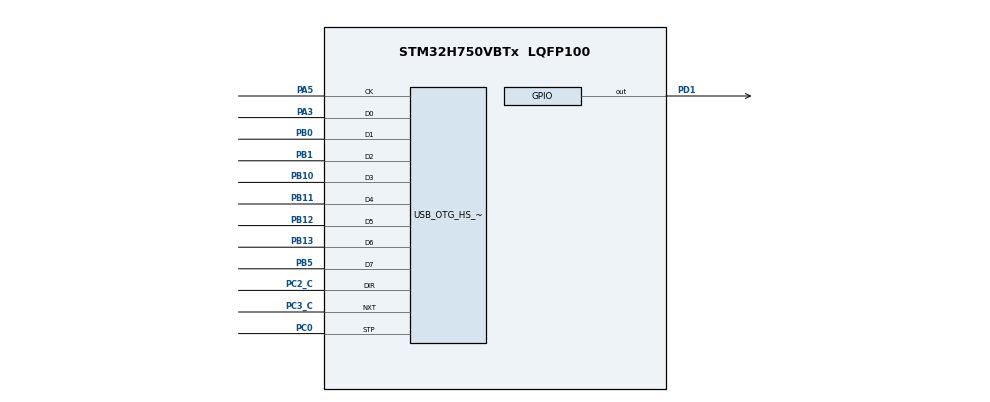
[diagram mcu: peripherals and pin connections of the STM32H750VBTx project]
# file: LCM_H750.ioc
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CORTEX_M7.AccessPermission-Cortex_Memory_Protection_Unit_Region0_Settings=MPU_REGION_FULL_ACCESS
CORTEX_M7.AccessPermission-Cortex_Memory_Protection_Unit_Region1_Settings=MPU_REGION_FULL_ACCESS
CORTEX_M7.AccessPermission-Cortex_Memory_Protection_Unit_Region2_Settings=MPU_REGION_FULL_ACCESS
CORTEX_M7.AccessPermission-Cortex_Memory_Protection_Unit_Region3_Settings=MPU_REGION_FULL_ACCESS
CORTEX_M7.AccessPermission_S-Cortex_Memory_Protection_Unit_Region1_Settings_S=MPU_REGION_FULL_ACCESS
CORTEX_M7.AccessPermission_S-Cortex_Memory_Protection_Unit_Region2_Settings_S=MPU_REGION_FULL_ACCESS
CORTEX_M7.AccessPermission_S-Cortex_Memory_Protection_Unit_Region3_Settings_S=MPU_REGION_FULL_ACCESS
CORTEX_M7.AccessPermission_Spec=MPU_REGION_FULL_ACCESS
CORTEX_M7.BaseAddress-Cortex_Memory_Protection_Unit_Region0_Settings=0x24000000
CORTEX_M7.BaseAddress-Cortex_Memory_Protection_Unit_Region1_Settings=0x30000000
CORTEX_M7.BaseAddress-Cortex_Memory_Protection_Unit_Region2_Settings=0x30040000
CORTEX_M7.BaseAddress-Cortex_Memory_Protection_Unit_Region3_Settings=0x38000000
CORTEX_M7.BaseAddress_S-Cortex_Memory_Protection_Unit_Region1_Settings_S=0x30000000
CORTEX_M7.BaseAddress_S-Cortex_Memory_Protection_Unit_Region2_Settings_S=0x30040000
CORTEX_M7.BaseAddress_S-Cortex_Memory_Protection_Unit_Region3_Settings_S=0x38000000
CORTEX_M7.BaseAddress_Spec=0x24000000
CORTEX_M7.CPU_DCache=Enabled
CORTEX_M7.CPU_ICache=Enabled
CORTEX_M7.DisableExec_Spec=MPU_INSTRUCTION_ACCESS_ENABLE
CORTEX_M7.Enable-Cortex_Memory_Protection_Unit_Region0_Settings=MPU_REGION_ENABLE
CORTEX_M7.Enable-Cortex_Memory_Protection_Unit_Region1_Settings=MPU_REGION_ENABLE
CORTEX_M7.Enable-Cortex_Memory_Protection_Unit_Region2_Settings=MPU_REGION_ENABLE
CORTEX_M7.Enable-Cortex_Memory_Protection_Unit_Region3_Settings=MPU_REGION_ENABLE
CORTEX_M7.Enable_S-Cortex_Memory_Protection_Unit_Region1_Settings_S=MPU_REGION_ENABLE
CORTEX_M7.Enable_S-Cortex_Memory_Protection_Unit_Region2_Settings_S=MPU_REGION_ENABLE
CORTEX_M7.Enable_S-Cortex_Memory_Protection_Unit_Region3_Settings_S=MPU_REGION_ENABLE
CORTEX_M7.IsBufferable-Cortex_Memory_Protection_Unit_Region0_Settings=MPU_ACCESS_BUFFERABLE
CORTEX_M7.IsBufferable-Cortex_Memory_Protection_Unit_Region1_Settings=MPU_ACCESS_BUFFERABLE
CORTEX_M7.IsBufferable-Cortex_Memory_Protection_Unit_Region2_Settings=MPU_ACCESS_BUFFERABLE
CORTEX_M7.IsBufferable-Cortex_Memory_Protection_Unit_Region3_Settings=MPU_ACCESS_BUFFERABLE
CORTEX_M7.IsBufferable_S-Cortex_Memory_Protection_Unit_Region1_Settings_S=MPU_ACCESS_BUFFERABLE
CORTEX_M7.IsBufferable_S-Cortex_Memory_Protection_Unit_Region2_Settings_S=MPU_ACCESS_BUFFERABLE
CORTEX_M7.IsBufferable_S-Cortex_Memory_Protection_Unit_Region3_Settings_S=MPU_ACCESS_BUFFERABLE
CORTEX_M7.IsShareable_Spec=MPU_ACCESS_NOT_SHAREABLE
CORTEX_M7.MPU_Control=MPU_HFNMI_PRIVDEF
CORTEX_M7.Size-Cortex_Memory_Protection_Unit_Region0_Settings=MPU_REGION_SIZE_512KB
CORTEX_M7.Size-Cortex_Memory_Protection_Unit_Region1_Settings=MPU_REGION_SIZE_256KB
CORTEX_M7.Size-Cortex_Memory_Protection_Unit_Region2_Settings=MPU_REGION_SIZE_32KB
CORTEX_M7.Size-Cortex_Memory_Protection_Unit_Region3_Settings=MPU_REGION_SIZE_64KB
CORTEX_M7.Size_S-Cortex_Memory_Protection_Unit_Region1_Settings_S=MPU_REGION_SIZE_256KB
CORTEX_M7.Size_S-Cortex_Memory_Protection_Unit_Region2_Settings_S=MPU_REGION_SIZE_32KB
CORTEX_M7.Size_S-Cortex_Memory_Protection_Unit_Region3_Settings_S=MPU_REGION_SIZE_64KB
CORTEX_M7.Size_Spec=MPU_REGION_SIZE_512KB
CORTEX_M7.SubRegionDisable_Spec=0
CORTEX_M7.TypeExtField-Cortex_Memory_Protection_Unit_Region0_Settings=MPU_TEX_LEVEL1
CORTEX_M7.TypeExtField-Cortex_Memory_Protection_Unit_Region1_Settings=MPU_TEX_LEVEL1
CORTEX_M7.TypeExtField-Cortex_Memory_Protection_Unit_Region2_Settings=MPU_TEX_LEVEL1
CORTEX_M7.TypeExtField-Cortex_Memory_Protection_Unit_Region3_Settings=MPU_TEX_LEVEL1
CORTEX_M7.TypeExtField_Spec=MPU_TEX_LEVEL1
CORTEX_M7.default_mode_Activation=1
Mcu.Family=STM32H7
Mcu.Name=STM32H750VBTx
Mcu.Package=LQFP100
NVIC.OTG_HS_IRQn=true\:0\:0\:false\:false\:true\:false\:true\:true\:true
NVIC.PriorityGroup=NVIC_PRIORITYGROUP_4
NVIC.TIM7_IRQn=true\:15\:0\:false\:false\:true\:false\:false\:true\:true
NVIC.TimeBase=TIM7_IRQn
NVIC.TimeBaseIP=TIM7
PA3.Mode=Device_HS
PA3.Signal=USB_OTG_HS_ULPI_D0
PA5.Mode=Device_HS
PA5.Signal=USB_OTG_HS_ULPI_CK
PB0.Mode=Device_HS
PB0.Signal=USB_OTG_HS_ULPI_D1
PB1.Mode=Device_HS
PB1.Signal=USB_OTG_HS_ULPI_D2
PB10.Mode=Device_HS
PB10.Signal=USB_OTG_HS_ULPI_D3
PB11.Mode=Device_HS
PB11.Signal=USB_OTG_HS_ULPI_D4
PB12.Mode=Device_HS
PB12.Signal=USB_OTG_HS_ULPI_D5
PB13.Mode=Device_HS
PB13.Signal=USB_OTG_HS_ULPI_D6
PB5.Mode=Device_HS
PB5.Signal=USB_OTG_HS_ULPI_D7
PC0.Mode=Device_HS
PC0.Signal=USB_OTG_HS_ULPI_STP
PC2_C.Mode=Device_HS
PC2_C.Signal=USB_OTG_HS_ULPI_DIR
PC3_C.Mode=Device_HS
PC3_C.Signal=USB_OTG_HS_ULPI_NXT
PD1.Signal=GPIO_Output
PH0-OSC_IN\ (PH0).Mode=HSE-External-Oscillator
PH0-OSC_IN\ (PH0).Signal=RCC_OSC_IN
PH1-OSC_OUT\ (PH1).Mode=HSE-External-Oscillator
PH1-OSC_OUT\ (PH1).Signal=RCC_OSC_OUT
ProjectManager.HeapSize=0x200
ProjectManager.StackSize=0x400
ProjectManager.TargetToolchain=Makefile
RCC.ADCFreq_Value=120000000
RCC.APB1Freq_Value=120000000
RCC.APB2Freq_Value=120000000
RCC.APB3Freq_Value=120000000
RCC.APB4Freq_Value=120000000
RCC.CortexFreq_Value=480000000
RCC.D1PPRE=RCC_APB3_DIV2
RCC.D2PPRE1=RCC_APB1_DIV2
RCC.D2PPRE2=RCC_APB2_DIV2
RCC.D3PPRE=RCC_APB4_DIV2
RCC.DIVM1=13
RCC.DIVM2=13
RCC.DIVM3=13
RCC.DIVN1=480
RCC.DIVN2=120
RCC.DIVN3=120
RCC.DIVQ3=5
RCC.HCLKFreq_Value=240000000
RCC.HPRE=RCC_HCLK_DIV2
RCC.HSE_VALUE=26000000
RCC.PLLSourceVirtual=RCC_PLLSOURCE_HSE
RCC.SYSCLKFreq_VALUE=480000000
RCC.SYSCLKSource=RCC_SYSCLKSOURCE_PLLCLK
RCC.USBCLockSelection=RCC_USBCLKSOURCE_PLL3
RCC.USBFreq_Value=48000000
STMicroelectronics.X-CUBE-AZRTOS-H7.2.0.0.ThreadXCcRTOSJjThreadXJjCore=true
STMicroelectronics.X-CUBE-AZRTOS-H7.2.0.0_IsAnAzureRtosMw=true
USB_OTG_HS.VirtualMode-Device_HS=Device_HS
VP_LPTIM3_VS_LPTIM_counterModeInternalClock.Mode=Counts__internal_clock_event_00
VP_STMicroelectronics.X-CUBE-AZRTOS-H7_VS_RTOSJjThreadX_6.1.7_2.0.0.Mode=RTOSJjThreadX
VP_SYS_VS_tim7.Mode=TIM7
board=custom

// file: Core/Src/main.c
/* USER CODE BEGIN Header */
/**
  ******************************************************************************
  * @file           : main.c
  * @brief          : Main program body
  ******************************************************************************
  * @attention
  *
  * Copyright (c) 2022 STMicroelectronics.
  * All rights reserved.
  *
  * This software is licensed under terms that can be found in the LICENSE file
  * in the root directory of this software component.
  * If no LICENSE file comes with this software, it is provided AS-IS.
  *
  ******************************************************************************
  */
/* USER CODE END Header */
#include "main.h"
#include "app_threadx.h"
#include "lptim.h"
#include "usb_otg.h"
#include "gpio.h"

void SystemClock_Config(void);
static void MPU_Config(void);

int main(void)
{

  /* MPU Configuration--------------------------------------------------------*/
  MPU_Config();

  /* Enable I-Cache---------------------------------------------------------*/
  SCB_EnableICache();

  /* Enable D-Cache---------------------------------------------------------*/
  SCB_EnableDCache();

  /* MCU Configuration--------------------------------------------------------*/

  /* Reset of all peripherals, Initializes the Flash interface and the Systick. */
  HAL_Init();

  /* Configure the system clock */
  SystemClock_Config();

  /* Initialize all configured peripherals */
  MX_GPIO_Init();
  MX_LPTIM3_Init();
  MX_USB_OTG_HS_PCD_Init();
  /* USER CODE BEGIN 2 */
  extern void MX_USB_DEVICE_Init();
  MX_USB_DEVICE_Init();

  /* USER CODE END 2 */

  MX_ThreadX_Init();

  /* We should never get here as control is now taken by the scheduler */
  /* Infinite loop */
  while (1)
  {

  }
}

void SystemClock_Config(void)
{
  RCC_OscInitTypeDef RCC_OscInitStruct = {0};
  RCC_ClkInitTypeDef RCC_ClkInitStruct = {0};

  /** Supply configuration update enable
  */
  HAL_PWREx_ConfigSupply(PWR_LDO_SUPPLY);

  /** Configure the main internal regulator output voltage
  */
  __HAL_PWR_VOLTAGESCALING_CONFIG(PWR_REGULATOR_VOLTAGE_SCALE0);

  while(!__HAL_PWR_GET_FLAG(PWR_FLAG_VOSRDY)) {}

  /** Macro to configure the PLL clock source
  */
  __HAL_RCC_PLL_PLLSOURCE_CONFIG(RCC_PLLSOURCE_HSE);

  /** Initializes the RCC Oscillators according to the specified parameters
  * in the RCC_OscInitTypeDef structure.
  */
  RCC_OscInitStruct.OscillatorType = RCC_OSCILLATORTYPE_HSE;
  RCC_OscInitStruct.HSEState = RCC_HSE_ON;
  RCC_OscInitStruct.PLL.PLLState = RCC_PLL_ON;
  RCC_OscInitStruct.PLL.PLLSource = RCC_PLLSOURCE_HSE;
  RCC_OscInitStruct.PLL.PLLM = 13;
  RCC_OscInitStruct.PLL.PLLN = 480;
  RCC_OscInitStruct.PLL.PLLP = 2;
  RCC_OscInitStruct.PLL.PLLQ = 2;
  RCC_OscInitStruct.PLL.PLLR = 2;
  RCC_OscInitStruct.PLL.PLLRGE = RCC_PLL1VCIRANGE_1;
  RCC_OscInitStruct.PLL.PLLVCOSEL = RCC_PLL1VCOWIDE;
  RCC_OscInitStruct.PLL.PLLFRACN = 0;
  if (HAL_RCC_OscConfig(&RCC_OscInitStruct) != HAL_OK)
  {
    Error_Handler();
  }

  /** Initializes the CPU, AHB and APB buses clocks
  */
  RCC_ClkInitStruct.ClockType = RCC_CLOCKTYPE_HCLK|RCC_CLOCKTYPE_SYSCLK
                              |RCC_CLOCKTYPE_PCLK1|RCC_CLOCKTYPE_PCLK2
                              |RCC_CLOCKTYPE_D3PCLK1|RCC_CLOCKTYPE_D1PCLK1;
  RCC_ClkInitStruct.SYSCLKSource = RCC_SYSCLKSOURCE_PLLCLK;
  RCC_ClkInitStruct.SYSCLKDivider = RCC_SYSCLK_DIV1;
  RCC_ClkInitStruct.AHBCLKDivider = RCC_HCLK_DIV2;
  RCC_ClkInitStruct.APB3CLKDivider = RCC_APB3_DIV2;
  RCC_ClkInitStruct.APB1CLKDivider = RCC_APB1_DIV2;
  RCC_ClkInitStruct.APB2CLKDivider = RCC_APB2_DIV2;
  RCC_ClkInitStruct.APB4CLKDivider = RCC_APB4_DIV2;

  if (HAL_RCC_ClockConfig(&RCC_ClkInitStruct, FLASH_LATENCY_4) != HAL_OK)
  {
    Error_Handler();
  }
}

/* MPU Configuration */

void MPU_Config(void)
{
  MPU_Region_InitTypeDef MPU_InitStruct = {0};

  /* Disables the MPU */
  HAL_MPU_Disable();

  /** Initializes and configures the Region and the memory to be protected
  */
  MPU_InitStruct.Enable = MPU_REGION_ENABLE;
  MPU_InitStruct.Number = MPU_REGION_NUMBER0;
  MPU_InitStruct.BaseAddress = 0x24000000;
  MPU_InitStruct.Size = MPU_REGION_SIZE_512KB;
  MPU_InitStruct.SubRegionDisable = 0x0;
  MPU_InitStruct.TypeExtField = MPU_TEX_LEVEL1;
  MPU_InitStruct.AccessPermission = MPU_REGION_FULL_ACCESS;
  MPU_InitStruct.DisableExec = MPU_INSTRUCTION_ACCESS_ENABLE;
  MPU_InitStruct.IsShareable = MPU_ACCESS_NOT_SHAREABLE;
  MPU_InitStruct.IsCacheable = MPU_ACCESS_NOT_CACHEABLE;
  MPU_InitStruct.IsBufferable = MPU_ACCESS_BUFFERABLE;

  HAL_MPU_ConfigRegion(&MPU_InitStruct);

  /** Initializes and configures the Region and the memory to be protected
  */
  MPU_InitStruct.Number = MPU_REGION_NUMBER1;
  MPU_InitStruct.BaseAddress = 0x30000000;
  MPU_InitStruct.Size = MPU_REGION_SIZE_256KB;

  HAL_MPU_ConfigRegion(&MPU_InitStruct);

  /** Initializes and configures the Region and the memory to be protected
  */
  MPU_InitStruct.Number = MPU_REGION_NUMBER2;
  MPU_InitStruct.BaseAddress = 0x30040000;
  MPU_InitStruct.Size = MPU_REGION_SIZE_32KB;

  HAL_MPU_ConfigRegion(&MPU_InitStruct);

  /** Initializes and configures the Region and the memory to be protected
  */
  MPU_InitStruct.Number = MPU_REGION_NUMBER3;
  MPU_InitStruct.BaseAddress = 0x38000000;
  MPU_InitStruct.Size = MPU_REGION_SIZE_64KB;

  HAL_MPU_ConfigRegion(&MPU_InitStruct);
  /* Enables the MPU */
  HAL_MPU_Enable(MPU_HFNMI_PRIVDEF);

}

void HAL_TIM_PeriodElapsedCallback(TIM_HandleTypeDef *htim)
{
  if (htim->Instance == TIM7) {
    HAL_IncTick();
  }
}

void Error_Handler(void)
{
  __disable_irq();
  while (1)
  {
  }
}
